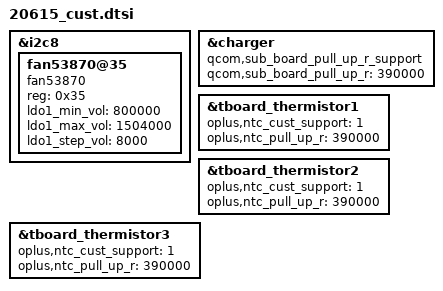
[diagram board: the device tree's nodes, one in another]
/*#ifdef VENDOE_EDIT*/
&i2c8 {
	   fan53870@35 {
               compatible = "fan53870";
               reg = <0x35>;
               ldo1_min_vol = <800000>;  /*uV*/
               ldo1_max_vol = <1504000>;
               ldo1_step_vol = <8000>;
       };
};
/*#endif*/

&charger {
	qcom,sub_board_pull_up_r_support;
	qcom,sub_board_pull_up_r = <390000>;
};

&tboard_thermistor1 {
    oplus,ntc_cust_support = <1>;
    oplus,ntc_pull_up_r = <390000>; /*390K*/
};

&tboard_thermistor2 {
    oplus,ntc_cust_support = <1>;
    oplus,ntc_pull_up_r = <390000>; /*390K*/
};

&tboard_thermistor3 {
    oplus,ntc_cust_support = <1>;
    oplus,ntc_pull_up_r = <390000>; /*390K*/
};
